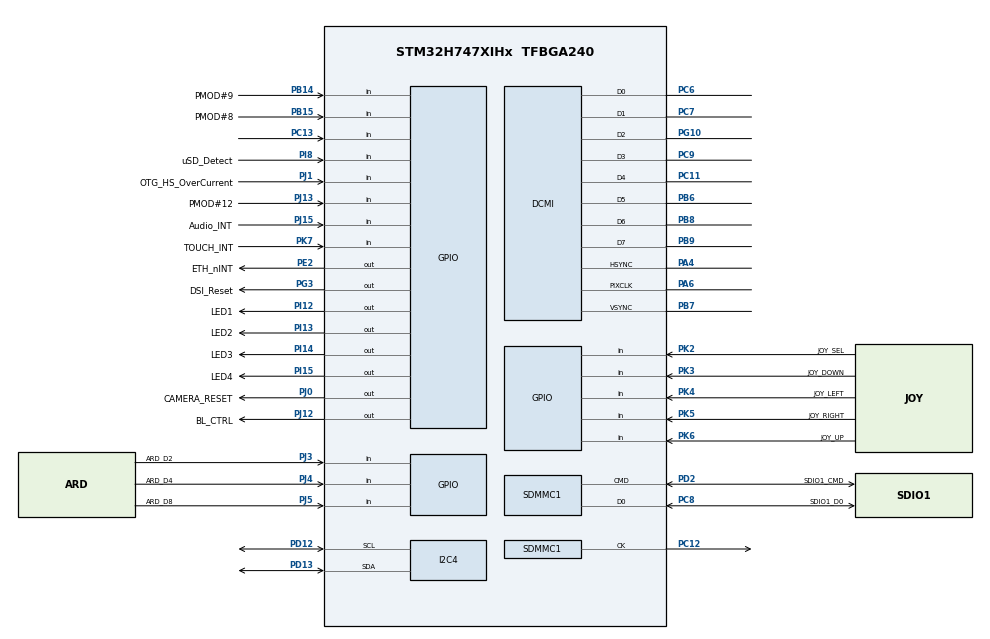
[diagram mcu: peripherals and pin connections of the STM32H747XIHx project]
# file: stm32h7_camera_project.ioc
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CortexM4.IPs=BDMA,DMA,FATFS_M4\:I,FREERTOS_M4\:I,IWDG2\:I,MDMA,NVIC2\:I,RCC,USB_DEVICE_M4\:I,USB_HOST_M4\:I,WWDG2\:I,TIM3\:I,PDM2PCM_M4\:I,PWR,RESMGR_UTILITY,SYS_M4\:I,CORTEX_M4\:I,GPIO,OPENAMP_M4\:I,VREFBUF,DEBUG
CortexM7.IPs=BDMA\:I,DMA\:I,FATFS_M7\:I,FREERTOS_M7\:I,IWDG1\:I,MDMA\:I,NVIC1\:I,RCC\:I,USB_DEVICE_M7\:I,USB_HOST_M7\:I,WWDG1\:I,CORTEX_M7\:I,DEBUG\:I,PDM2PCM_M7\:I,PWR\:I,RESMGR_UTILITY\:I,SYS\:I,GPIO\:I,OPENAMP_M7\:I,VREFBUF\:I,MEMORYMAP\:I,DCMI\:I,LTDC\:I,DSIHOST\:I,I2C4\:I,SDMMC1\:I
CortexM7.Pins=PC13,PJ0
DCMI.PCKPolarity=DCMI_PCKPOLARITY_RISING
DCMI.VSPolarity=DCMI_VSPOLARITY_HIGH
Dma.DCMI.0.Direction=DMA_PERIPH_TO_MEMORY
Dma.DCMI.0.EventEnable=DISABLE
Dma.DCMI.0.FIFOMode=DMA_FIFOMODE_DISABLE
Dma.DCMI.0.Instance=DMA1_Stream0
Dma.DCMI.0.MemDataAlignment=DMA_MDATAALIGN_WORD
Dma.DCMI.0.MemInc=DMA_MINC_ENABLE
Dma.DCMI.0.Mode=DMA_NORMAL
Dma.DCMI.0.PeriphDataAlignment=DMA_PDATAALIGN_WORD
Dma.DCMI.0.PeriphInc=DMA_PINC_DISABLE
Dma.DCMI.0.Polarity=HAL_DMAMUX_REQ_GEN_RISING
Dma.DCMI.0.Priority=DMA_PRIORITY_LOW
Dma.DCMI.0.RequestNumber=1
Dma.DCMI.0.SignalID=NONE
Dma.DCMI.0.SyncEnable=DISABLE
Dma.DCMI.0.SyncPolarity=HAL_DMAMUX_SYNC_NO_EVENT
Dma.DCMI.0.SyncRequestNumber=1
Dma.DCMI.0.SyncSignalID=NONE
Dma.Request0=DCMI
FATFS.BSP.number=1
FATFS0.BSP.STBoard=false
FATFS0.BSP.api=Unknown
FATFS0.BSP.instance=PI8
FATFS0.BSP.ip=GPIO
FATFS0.BSP.mode=Input
FATFS0.BSP.name=Detect_SDIO
FATFS0.BSP.solution=PI8
FATFS_M7.USE_DMA_CODE_SD=1
I2C4.Timing=0x10C0ECFF
Mcu.Family=STM32H7
Mcu.Name=STM32H747XIHx
Mcu.Package=TFBGA240
NVIC1.DCMI_IRQn=true\:0\:0\:false\:false\:true\:true\:true\:true
NVIC1.DMA1_Stream0_IRQn=true\:0\:0\:false\:false\:true\:false\:true\:true
NVIC1.PriorityGroup=NVIC_PRIORITYGROUP_4
NVIC1.SDMMC1_IRQn=true\:0\:0\:false\:false\:true\:true\:true\:true
NVIC2.PriorityGroup=NVIC_PRIORITYGROUP_4
PA0.GPIO_Label=PMOD\#1- USART2_CTS_NSS
PA0.Signal=USART2_CTS
PA0_C.GPIO_Label=ARD_A2
PA0_C.Signal=ADCx_INP0
PA1.GPIO_Label=ETH_REF_CLK
PA1.Signal=ETH_REF_CLK
PA10.GPIO_Label=STLINK_TX
PA10.Signal=USART1_RX
PA11.GPIO_Label=PMOD\#1
PA11.Signal=SPI2_NSS
PA12.GPIO_Label=SPI2_SCK
PA12.Signal=SPI2_SCK
PA13\ (JTMS/SWDIO).Mode=Serial_Wire
PA13\ (JTMS/SWDIO).PinAttribute=CortexM7
PA13\ (JTMS/SWDIO).Signal=DEBUG_JTMS-SWDIO
PA14\ (JTCK/SWCLK).Mode=Serial_Wire
PA14\ (JTCK/SWCLK).PinAttribute=CortexM7
PA14\ (JTCK/SWCLK).Signal=DEBUG_JTCK-SWCLK
PA1_C.GPIO_Label=ARD_A3
PA1_C.Signal=ADCx_INP1
PA2.GPIO_Label=ETH_MDIO
PA2.Signal=ETH_MDIO
PA3.GPIO_Label=ULPI_D0
PA3.Signal=USB_OTG_HS_ULPI_D0
PA4.GPIO_PuPd=GPIO_PULLDOWN
PA4.GPIO_Speed=GPIO_SPEED_FREQ_VERY_HIGH
PA4.Mode=Slave_8_bits_External_Synchro
PA4.PinAttribute=CortexM7
PA4.Signal=DCMI_HSYNC
PA5.GPIO_Label=ULPI_CK
PA5.Signal=USB_OTG_HS_ULPI_CK
PA6.GPIO_PuPd=GPIO_PULLDOWN
PA6.GPIO_Speed=GPIO_SPEED_FREQ_VERY_HIGH
PA6.Mode=Slave_8_bits_External_Synchro
PA6.PinAttribute=CortexM7
PA6.Signal=DCMI_PIXCLK
PA7.GPIO_Label=ETH_CRS_DV
PA7.Signal=ETH_CRS_DV
PA8.GPIO_Label=CEC_CK/MCO1
PA8.PinAttribute=Free
PA8.Signal=RCC_MCO_1
PA9.GPIO_Label=STLINK_RX
PA9.Signal=USART1_TX
PB0.GPIO_Label=ULPI_D1
PB0.Signal=USB_OTG_HS_ULPI_D1
PB1.GPIO_Label=ULPI_D2
PB1.Signal=USB_OTG_HS_ULPI_D2
PB10.GPIO_Label=ULPI_D3
PB10.Signal=USB_OTG_HS_ULPI_D3
PB11.GPIO_Label=ULPI_D4
PB11.Signal=USB_OTG_HS_ULPI_D4
PB12.GPIO_Label=ULPI_D5
PB12.Signal=USB_OTG_HS_ULPI_D5
PB13.GPIO_Label=ULPI_D6
PB13.Signal=USB_OTG_HS_ULPI_D6
PB14.GPIO_Label=PMOD\#9
PB14.PinAttribute=Free
PB14.Signal=GPIO_Input
PB15.GPIO_Label=PMOD\#8
PB15.PinAttribute=Free
PB15.Signal=GPIO_Input
PB2.GPIO_Label=QSPI_CLK
PB2.Signal=QUADSPI_CLK
PB5.GPIO_Label=ULPI_D7
PB5.Signal=USB_OTG_HS_ULPI_D7
PB6.GPIO_PuPd=GPIO_PULLDOWN
PB6.GPIO_Speed=GPIO_SPEED_FREQ_VERY_HIGH
PB6.Mode=Slave_8_bits_External_Synchro
PB6.PinAttribute=CortexM7
PB6.Signal=DCMI_D5
PB7.GPIO_PuPd=GPIO_PULLDOWN
PB7.GPIO_Speed=GPIO_SPEED_FREQ_VERY_HIGH
PB7.Mode=Slave_8_bits_External_Synchro
PB7.PinAttribute=CortexM7
PB7.Signal=DCMI_VSYNC
PB8.GPIO_PuPd=GPIO_PULLDOWN
PB8.GPIO_Speed=GPIO_SPEED_FREQ_VERY_HIGH
PB8.Mode=Slave_8_bits_External_Synchro
PB8.PinAttribute=CortexM7
PB8.Signal=DCMI_D6
PB9.GPIO_PuPd=GPIO_PULLDOWN
PB9.GPIO_Speed=GPIO_SPEED_FREQ_VERY_HIGH
PB9.Mode=Slave_8_bits_External_Synchro
PB9.PinAttribute=CortexM7
PB9.Signal=DCMI_D7
PC0.GPIO_Label=ULPI_STP
PC0.Signal=USB_OTG_HS_ULPI_STP
PC1.GPIO_Label=ETH_MDC/SAI4_D1
PC1.Signal=ETH_MDC
PC10.GPIO_Label=SDIO1_D2
PC10.PinAttribute=CortexM7
PC10.Signal=SDMMC1_D2
PC11.GPIO_PuPd=GPIO_PULLDOWN
PC11.GPIO_Speed=GPIO_SPEED_FREQ_VERY_HIGH
PC11.Mode=Slave_8_bits_External_Synchro
PC11.PinAttribute=CortexM7
PC11.Signal=DCMI_D4
PC12.Mode=SD_1_bit
PC12.PinAttribute=CortexM7
PC12.Signal=SDMMC1_CK
PC13.GPIO_PuPd=GPIO_PULLDOWN
PC13.PinAttribute=CortexM7
PC13.Signal=GPIO_Input
PC14-OSC32_IN\ (OSC32_IN).GPIO_Label=OSC32_IN
PC14-OSC32_IN\ (OSC32_IN).PinAttribute=Free
PC14-OSC32_IN\ (OSC32_IN).Signal=RCC_OSC32_IN
PC15-OSC32_OUT\ (OSC32_OUT).GPIO_Label=OSC32_OUT
PC15-OSC32_OUT\ (OSC32_OUT).PinAttribute=Free
PC15-OSC32_OUT\ (OSC32_OUT).Signal=RCC_OSC32_OUT
PC2.GPIO_Label=PMOD\#3
PC2.Signal=SPI2_MISO
PC2_C.GPIO_Label=ARD_A4
PC2_C.Signal=ADC3_INP0
PC3.GPIO_Label=PMOD\#2
PC3.Signal=SPI2_MOSI
PC3_C.GPIO_Label=ARD_A5
PC3_C.Signal=ADC3_INP1
PC4.GPIO_Label=ETH_RXD0
PC4.Signal=ETH_RXD0
PC5.GPIO_Label=ETH_RXD1
PC5.Signal=ETH_RXD1
PC6.GPIO_PuPd=GPIO_PULLDOWN
PC6.GPIO_Speed=GPIO_SPEED_FREQ_VERY_HIGH
PC6.Mode=Slave_8_bits_External_Synchro
PC6.PinAttribute=CortexM7
PC6.Signal=DCMI_D0
PC7.GPIO_PuPd=GPIO_PULLDOWN
PC7.GPIO_Speed=GPIO_SPEED_FREQ_VERY_HIGH
PC7.Mode=Slave_8_bits_External_Synchro
PC7.PinAttribute=CortexM7
PC7.Signal=DCMI_D1
PC8.GPIO_Label=SDIO1_D0
PC8.Mode=SD_1_bit
PC8.PinAttribute=CortexM7
PC8.Signal=SDMMC1_D0
PC9.GPIO_PuPd=GPIO_PULLDOWN
PC9.GPIO_Speed=GPIO_SPEED_FREQ_VERY_HIGH
PC9.Mode=Slave_8_bits_External_Synchro
PC9.PinAttribute=CortexM7
PC9.Signal=DCMI_D3
PD0.GPIO_Label=FMC_D2
PD0.Signal=FMC_D2_DA2
PD1.GPIO_Label=FMC_D3
PD1.Signal=FMC_D3_DA3
PD10.GPIO_Label=FMC_D15
PD10.Signal=FMC_D15_DA15
PD11.GPIO_Label=QSPI_BK1_IO0
PD11.Signal=QUADSPI_BK1_IO0
PD12.GPIO_Pu=GPIO_PULLUP
PD12.Mode=I2C
PD12.PinAttribute=CortexM7
PD12.Signal=I2C4_SCL
PD13.GPIO_Pu=GPIO_PULLUP
PD13.Mode=I2C
PD13.PinAttribute=CortexM7
PD13.Signal=I2C4_SDA
PD14.GPIO_Label=FMC_D0
PD14.Signal=FMC_D0_DA0
PD15.GPIO_Label=FMC_D1
PD15.Signal=FMC_D1_DA1
PD2.GPIO_Label=SDIO1_CMD
PD2.Mode=SD_1_bit
PD2.PinAttribute=CortexM7
PD2.Signal=SDMMC1_CMD
PD3.GPIO_Label=PMOD\#18_DFSDM_CKOUT
PD3.Signal=S_CKOUTDFSDM1
PD4.GPIO_Label=PMOD\#4- USART2_RTS
PD4.Signal=USART2_RTS
PD5.GPIO_Label=PMOD\#2- USART2_TX
PD5.Signal=USART2_TX
PD6.GPIO_Label=PMOD\#3- USART2_RX
PD6.Signal=USART2_RX
PD7.GPIO_Label=SPDIF_RX0
PD7.Signal=SPDIFRX1_IN0
PD8.GPIO_Label=FMC_D13
PD8.Signal=FMC_D13_DA13
PD9.GPIO_Label=FMC_D14
PD9.Signal=FMC_D14_DA14
PE0.GPIO_Label=FMC_NBL0
PE0.Signal=FMC_NBL0
PE1.GPIO_Label=FMC_NBL1
PE1.Signal=FMC_NBL1
PE10.GPIO_Label=FMC_D7
PE10.Signal=FMC_D7_DA7
PE11.GPIO_Label=FMC_D8
PE11.Signal=FMC_D8_DA8
PE12.GPIO_Label=FMC_D9
PE12.Signal=FMC_D9_DA9
PE13.GPIO_Label=FMC_D10
PE13.Signal=FMC_D10_DA10
PE14.GPIO_Label=FMC_D11
PE14.Signal=FMC_D11_DA11
PE15.GPIO_Label=FMC_D12
PE15.Signal=FMC_D12_DA12
PE2.GPIO_Label=ETH_nINT
PE2.PinAttribute=Free
PE2.Signal=GPIO_Output
PE3.GPIO_Label=SAI1_SD_B
PE3.Signal=SAI1_SD_B
PE4.GPIO_Label=SAI1_FS_A
PE4.Signal=SAI1_FS_A
PE5.GPIO_Label=SAI1_SCK_A
PE5.Signal=SAI1_SCK_A
PE6.GPIO_Label=SAI1_SD_A
PE6.Signal=SAI1_SD_A
PE7.GPIO_Label=FMC_D4
PE7.Signal=FMC_D4_DA4
PE8.GPIO_Label=FMC_D5
PE8.Signal=FMC_D5_DA5
PE9.GPIO_Label=FMC_D6
PE9.Signal=FMC_D6_DA6
PF0.GPIO_Label=FMC_A0
PF0.Signal=FMC_A0
PF1.GPIO_Label=FMC_A1
PF1.Signal=FMC_A1
PF10.GPIO_Label=ARD_A1
PF10.Signal=ADC3_INP6
PF11.GPIO_Label=FMC_SDRAS
PF11.Signal=FMC_SDNRAS
PF12.GPIO_Label=FMC_A6
PF12.Signal=FMC_A6
PF13.GPIO_Label=FMC_A7
PF13.Signal=FMC_A7
PF14.GPIO_Label=FMC_A8
PF14.Signal=FMC_A8
PF15.GPIO_Label=FMC_A9
PF15.Signal=FMC_A9
PF2.GPIO_Label=FMC_A2
PF2.Signal=FMC_A2
PF3.GPIO_Label=FMC_A3
PF3.Signal=FMC_A3
PF4.GPIO_Label=FMC_A4
PF4.Signal=FMC_A4
PF5.GPIO_Label=FMC_A5
PF5.Signal=FMC_A5
PF6.GPIO_Label=QSPI_BK1_IO3
PF6.Signal=QUADSPI_BK1_IO3
PF7.GPIO_Label=QSPI_BK1_IO2
PF7.Signal=QUADSPI_BK1_IO2
PF8.GPIO_Label=PMOD\#14/ARD_D3
PF8.Signal=S_TIM13_CH1
PF9.GPIO_Label=QSPI_BK1_IO1
PF9.Signal=QUADSPI_BK1_IO1
PG0.GPIO_Label=FMC_A10
PG0.Signal=FMC_A10
PG1.GPIO_Label=FMC_A11
PG1.Signal=FMC_A11
PG10.GPIO_PuPd=GPIO_PULLDOWN
PG10.GPIO_Speed=GPIO_SPEED_FREQ_VERY_HIGH
PG10.Mode=Slave_8_bits_External_Synchro
PG10.PinAttribute=CortexM7
PG10.Signal=DCMI_D2
PG11.GPIO_Label=ETH_TX_EN
PG11.Signal=ETH_TX_EN
PG12.GPIO_Label=ETH_TXD1
PG12.Signal=ETH_TXD1
PG13.GPIO_Label=ETH_TXD0
PG13.Signal=ETH_TXD0
PG14.GPIO_Label=QSPI_BK2_IO3
PG14.Signal=QUADSPI_BK2_IO3
PG15.GPIO_Label=FMC_SDCAS
PG15.Signal=FMC_SDNCAS
PG2.GPIO_Label=FMC_A12
PG2.Signal=FMC_A12
PG3.GPIO_Label=DSI_Reset
PG3.PinAttribute=Free
PG3.Signal=GPIO_Output
PG4.GPIO_Label=FMC_BA0
PG4.Signal=FMC_A14_BA0
PG5.Signal=FMC_A15_BA1
PG6.GPIO_Label=QSPI_BK1_NCS
PG6.Signal=QUADSPI_BK1_NCS
PG7.GPIO_Label=SAI1_MCLK_A
PG7.Signal=SAI1_MCLK_A
PG8.GPIO_Label=FMC_SDCLK
PG8.Signal=FMC_SDCLK
PG9.GPIO_Label=QSPI_BK2_IO2
PG9.Signal=QUADSPI_BK2_IO2
PH0-OSC_IN\ (PH0).GPIO_Label=OSC_IN
PH0-OSC_IN\ (PH0).Mode=HSE-External-Oscillator
PH0-OSC_IN\ (PH0).PinAttribute=Free
PH0-OSC_IN\ (PH0).Signal=RCC_OSC_IN
PH1-OSC_OUT\ (PH1).GPIO_Label=OSC_OUT
PH1-OSC_OUT\ (PH1).Mode=HSE-External-Oscillator
PH1-OSC_OUT\ (PH1).PinAttribute=Free
PH1-OSC_OUT\ (PH1).Signal=RCC_OSC_OUT
PH10.GPIO_Label=FMC_D18
PH10.Signal=FMC_D18
PH11.GPIO_Label=FMC_D19
PH11.Signal=FMC_D19
PH12.GPIO_Label=FMC_D20
PH12.Signal=FMC_D20
PH13.GPIO_Label=FMC_D21
PH13.Signal=FMC_D21
PH14.GPIO_Label=FMC_D22
PH14.Signal=FMC_D22
PH15.GPIO_Label=FMC_D23
PH15.Signal=FMC_D23
PH2.GPIO_Label=QSPI_BK2_IO0
PH2.Signal=QUADSPI_BK2_IO0
PH3.GPIO_Label=QSPI_BK2_IO1
PH3.Signal=QUADSPI_BK2_IO1
PH4.GPIO_Label=ULPI_NXT
PH4.Signal=USB_OTG_HS_ULPI_NXT
PH5.GPIO_Label=FMC_SDNWE
PH5.Signal=FMC_SDNWE
PH6.GPIO_Label=FMC_SDNE1
PH6.Signal=FMC_SDNE1
PH7.GPIO_Label=FMC_SDCKE1
PH7.Signal=FMC_SDCKE1
PH8.GPIO_Label=FMC_D16
PH8.Signal=FMC_D16
PH9.GPIO_Label=FMC_D17
PH9.Signal=FMC_D17
PI0.GPIO_Label=FMC_D24
PI0.Signal=FMC_D24
PI1.GPIO_Label=FMC_D25
PI1.Signal=FMC_D25
PI10.GPIO_Label=FMC_D31
PI10.Signal=FMC_D31
PI11.GPIO_Label=ULPI_DIR
PI11.Signal=USB_OTG_HS_ULPI_DIR
PI12.GPIO_Label=LED1
PI12.PinAttribute=Free
PI12.Signal=GPIO_Output
PI13.GPIO_Label=LED2
PI13.PinAttribute=Free
PI13.Signal=GPIO_Output
PI14.GPIO_Label=LED3
PI14.PinAttribute=Free
PI14.Signal=GPIO_Output
PI15.GPIO_Label=LED4
PI15.PinAttribute=Free
PI15.Signal=GPIO_Output
PI2.GPIO_Label=FMC_D26
PI2.Signal=FMC_D26
PI3.GPIO_Label=FMC_D27
PI3.Signal=FMC_D27
PI4.GPIO_Label=FMC_NBL2
PI4.Signal=FMC_NBL2
PI5.GPIO_Label=FMC_NBL3
PI5.Signal=FMC_NBL3
PI6.GPIO_Label=FMC_D28
PI6.Signal=FMC_D28
PI7.GPIO_Label=FMC_D29
PI7.Signal=FMC_D29
PI8.GPIO_Label=uSD_Detect
PI8.PinAttribute=Free
PI8.Signal=GPIO_Input
PI9.GPIO_Label=FMC_D30
PI9.Signal=FMC_D30
PJ0.GPIO_Label=CAMERA_RESET
PJ0.GPIO_PuPd=GPIO_PULLUP
PJ0.PinAttribute=CortexM7
PJ0.Signal=GPIO_Output
PJ1.GPIO_Label=OTG_HS_OverCurrent
PJ1.PinAttribute=Free
PJ1.Signal=GPIO_Input
PJ10.GPIO_Label=ARD_D11
PJ10.Signal=SPI5_MOSI
PJ11.GPIO_Label=ARD_D12
PJ11.Signal=SPI5_MISO
PJ12.GPIO_Label=BL_CTRL
PJ12.PinAttribute=Free
PJ12.Signal=GPIO_Output
PJ13.GPIO_Label=PMOD\#12
PJ13.PinAttribute=Free
PJ13.Signal=GPIO_Input
PJ15.GPIO_Label=Audio_INT
PJ15.PinAttribute=Free
PJ15.Signal=GPIO_Input
PJ3.GPIO_Label=ARD_D2
PJ3.PinAttribute=Free
PJ3.Signal=GPIO_Input
PJ4.GPIO_Label=ARD_D4
PJ4.PinAttribute=Free
PJ4.Signal=GPIO_Input
PJ5.GPIO_Label=ARD_D8
PJ5.PinAttribute=Free
PJ5.Signal=GPIO_Input
PJ6.GPIO_Label=ARD_D9
PJ6.Signal=S_TIM8_CH2
PJ7.GPIO_Label=ARD_D6
PJ7.Signal=TIM8_CH2N
PJ8.GPIO_Label=ARD_D1
PJ8.Signal=UART8_TX
PJ9.GPIO_Label=ARD_D0
PJ9.Signal=UART8_RX
PK0.GPIO_Label=ARD_D13
PK0.Signal=SPI5_SCK
PK1.GPIO_Label=ARD_D10
PK1.Signal=SPI5_NSS
PK2.GPIO_Label=JOY_SEL
PK2.PinAttribute=Free
PK2.Signal=GPIO_Input
PK3.GPIO_Label=JOY_DOWN
PK3.PinAttribute=Free
PK3.Signal=GPIO_Input
PK4.GPIO_Label=JOY_LEFT
PK4.PinAttribute=Free
PK4.Signal=GPIO_Input
PK5.GPIO_Label=JOY_RIGHT
PK5.PinAttribute=Free
PK5.Signal=GPIO_Input
PK6.GPIO_Label=JOY_UP
PK6.PinAttribute=Free
PK6.Signal=GPIO_Input
PK7.GPIO_Label=TOUCH_INT
PK7.PinAttribute=Free
PK7.Signal=GPIO_Input
ProjectManager.HeapSize=M4-0x400,M7-0x400
ProjectManager.StackSize=M4-0x800,M7-0x800
ProjectManager.TargetToolchain=STM32CubeIDE
RCC.ADCFreq_Value=150000000
RCC.APB1Freq_Value=100000000
RCC.APB2Freq_Value=100000000
RCC.APB3Freq_Value=100000000
RCC.APB4Freq_Value=100000000
RCC.CortexFreq_Value=200000000
RCC.D1PPRE=RCC_APB3_DIV2
RCC.D2PPRE1=RCC_APB1_DIV2
RCC.D2PPRE2=RCC_APB2_DIV2
RCC.D3PPRE=RCC_APB4_DIV2
RCC.DIVM1=2
RCC.DIVM2=2
RCC.DIVN1=32
RCC.DIVN2=12
RCC.DIVP2=1
RCC.DIVR2=1
RCC.HCLKFreq_Value=200000000
RCC.PLL2FRACN=0
RCC.PLLFRACN=0
RCC.PLLSourceVirtual=RCC_PLLSOURCE_HSE
RCC.PWR_Regulator_Voltage_Scale=PWR_REGULATOR_VOLTAGE_SCALE1
RCC.SDMMC1CLockSelection=RCC_SDMMCCLKSOURCE_PLL2
RCC.SYSCLKFreq_VALUE=200000000
RCC.SYSCLKSource=RCC_SYSCLKSOURCE_PLLCLK
RCC.SupplySource=PWR_DIRECT_SMPS_SUPPLY
RCC.USBFreq_Value=200000000
SH.ADCx_INP0.0=ADC1_INP0
SH.ADCx_INP1.0=ADC1_INP1
SH.FMC_A0.0=FMC_A0
SH.FMC_A1.0=FMC_A1
SH.FMC_A10.0=FMC_A10
SH.FMC_A11.0=FMC_A11
SH.FMC_A12.0=FMC_A12
SH.FMC_A14_BA0.0=FMC_BA0
SH.FMC_A15_BA1.0=FMC_BA1
SH.FMC_A2.0=FMC_A2
SH.FMC_A3.0=FMC_A3
SH.FMC_A4.0=FMC_A4
SH.FMC_A5.0=FMC_A5
SH.FMC_A6.0=FMC_A6
SH.FMC_A7.0=FMC_A7
SH.FMC_A8.0=FMC_A8
SH.FMC_A9.0=FMC_A9
SH.FMC_D0_DA0.0=FMC_D0
SH.FMC_D10_DA10.0=FMC_D10
SH.FMC_D11_DA11.0=FMC_D11
SH.FMC_D12_DA12.0=FMC_D12
SH.FMC_D13_DA13.0=FMC_D13
SH.FMC_D14_DA14.0=FMC_D14
SH.FMC_D15_DA15.0=FMC_D15
SH.FMC_D16.0=FMC_D16
SH.FMC_D17.0=FMC_D17
SH.FMC_D18.0=FMC_D18
SH.FMC_D19.0=FMC_D19
SH.FMC_D1_DA1.0=FMC_D1
SH.FMC_D20.0=FMC_D20
SH.FMC_D21.0=FMC_D21
SH.FMC_D22.0=FMC_D22
SH.FMC_D23.0=FMC_D23
SH.FMC_D24.0=FMC_D24
SH.FMC_D25.0=FMC_D25
SH.FMC_D26.0=FMC_D26
SH.FMC_D27.0=FMC_D27
SH.FMC_D28.0=FMC_D28
SH.FMC_D29.0=FMC_D29
SH.FMC_D2_DA2.0=FMC_D2
SH.FMC_D30.0=FMC_D30
SH.FMC_D31.0=FMC_D31
SH.FMC_D3_DA3.0=FMC_D3
SH.FMC_D4_DA4.0=FMC_D4
SH.FMC_D5_DA5.0=FMC_D5
SH.FMC_D6_DA6.0=FMC_D6
SH.FMC_D7_DA7.0=FMC_D7
SH.FMC_D8_DA8.0=FMC_D8
SH.FMC_D9_DA9.0=FMC_D9
SH.FMC_NBL0.0=FMC_NBL0
SH.FMC_NBL1.0=FMC_NBL1
SH.FMC_NBL2.0=FMC_NBL2
SH.FMC_NBL3.0=FMC_NBL3
SH.FMC_SDCLK.0=FMC_SDCLK
SH.FMC_SDNCAS.0=FMC_SDNCAS
SH.FMC_SDNRAS.0=FMC_SDNRAS
SH.FMC_SDNWE.0=FMC_SDNWE
SH.S_CKOUTDFSDM1.0=DFSDM1_CKOUT
SH.S_TIM13_CH1.0=TIM13_CH1
SH.S_TIM8_CH2.0=TIM8_CH2
VP_FATFS_M7_VS_SDIO.Mode=SDIO
VP_MEMORYMAP_VS_MEMORYMAP.Mode=CurAppReg
VP_SYS_M4_VS_Systick.Mode=SysTick
board=STM32H747I-DISC1

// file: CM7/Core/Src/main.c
/* USER CODE BEGIN Header */
/**
  ******************************************************************************
  * @file           : main.c
  * @brief          : Main program body
  ******************************************************************************
  * @attention
  *
  * Copyright (c) 2025 STMicroelectronics.
  * All rights reserved.
  *
  * This software is licensed under terms that can be found in the LICENSE file
  * in the root directory of this software component.
  * If no LICENSE file comes with this software, it is provided AS-IS.
  *
  ******************************************************************************
  */
/* USER CODE END Header */
#include "main.h"
#include "fatfs.h"

/* USER CODE BEGIN Includes */
#include "common.h"
#include "ov7670.h"

/* USER CODE END Includes */

/* USER CODE BEGIN PD */

#ifndef HSEM_ID_0
#define HSEM_ID_0 (0U) /* HW semaphore 0*/
#endif

/* USER CODE END PD */

DCMI_HandleTypeDef hdcmi;
DMA_HandleTypeDef hdma_dcmi;

I2C_HandleTypeDef hi2c4;

SD_HandleTypeDef hsd1;

void SystemClock_Config(void);
static void MX_GPIO_Init(void);
static void MX_DMA_Init(void);
static void MX_DCMI_Init(void);
static void MX_I2C4_Init(void);
static void MX_SDMMC1_SD_Init(void);

/* USER CODE BEGIN 0 */
int prev_button_state = 0;
/* USER CODE END 0 */

int main(void)
{

/* USER CODE BEGIN Boot_Mode_Sequence_0 */
  int32_t timeout;
/* USER CODE END Boot_Mode_Sequence_0 */

/* USER CODE BEGIN Boot_Mode_Sequence_1 */
  /* Wait until CPU2 boots and enters in stop mode or timeout*/
  timeout = 0xFFFF;
  while((__HAL_RCC_GET_FLAG(RCC_FLAG_D2CKRDY) != RESET) && (timeout-- > 0));
  if ( timeout < 0 )
  {
  Error_Handler();
  }
/* USER CODE END Boot_Mode_Sequence_1 */
  /* MCU Configuration--------------------------------------------------------*/

  /* Reset of all peripherals, Initializes the Flash interface and the Systick. */
  HAL_Init();

  /* Configure the system clock */
  SystemClock_Config();
/* USER CODE BEGIN Boot_Mode_Sequence_2 */
/* When system initialization is finished, Cortex-M7 will release Cortex-M4 by means of
HSEM notification */
/*HW semaphore Clock enable*/
__HAL_RCC_HSEM_CLK_ENABLE();
/*Take HSEM */
HAL_HSEM_FastTake(HSEM_ID_0);
/*Release HSEM in order to notify the CPU2(CM4)*/
HAL_HSEM_Release(HSEM_ID_0,0);
/* wait until CPU2 wakes up from stop mode */
timeout = 0xFFFF;
while((__HAL_RCC_GET_FLAG(RCC_FLAG_D2CKRDY) == RESET) && (timeout-- > 0));
if ( timeout < 0 )
{
Error_Handler();
}
/* USER CODE END Boot_Mode_Sequence_2 */

  /* Initialize all configured peripherals */
  MX_GPIO_Init();
  MX_DMA_Init();
  MX_DCMI_Init();
  MX_I2C4_Init();
  MX_SDMMC1_SD_Init();
  MX_FATFS_Init();
  /* USER CODE BEGIN 2 */

  ov7670_init(&hdcmi, &hdcmi, &hi2c4);

  ov7670_config(OV7670_MODE_QVGA_RGB565);

  /* USER CODE END 2 */

  /* Infinite loop */
  /* USER CODE BEGIN WHILE */
  while (1)
  {

	 HAL_Delay(10);
	 int button_state = HAL_GPIO_ReadPin(GPIOC, GPIO_PIN_13);
	 if (button_state && !prev_button_state)
	 {
		 ov7670_startCap(OV7670_CAP_SINGLE_FRAME,CAM_BUFFER);
		 writeBMPfile();
	 }
	 prev_button_state = button_state;

    /* USER CODE END WHILE */

  }
}

void SystemClock_Config(void)
{
  RCC_OscInitTypeDef RCC_OscInitStruct = {0};
  RCC_ClkInitTypeDef RCC_ClkInitStruct = {0};

  /** Supply configuration update enable
  */
  HAL_PWREx_ConfigSupply(PWR_DIRECT_SMPS_SUPPLY);

  /** Configure the main internal regulator output voltage
  */
  __HAL_PWR_VOLTAGESCALING_CONFIG(PWR_REGULATOR_VOLTAGE_SCALE1);

  while(!__HAL_PWR_GET_FLAG(PWR_FLAG_VOSRDY)) {}

  /** Initializes the RCC Oscillators according to the specified parameters
  * in the RCC_OscInitTypeDef structure.
  */
  RCC_OscInitStruct.OscillatorType = RCC_OSCILLATORTYPE_HSE;
  RCC_OscInitStruct.HSEState = RCC_HSE_ON;
  RCC_OscInitStruct.PLL.PLLState = RCC_PLL_ON;
  RCC_OscInitStruct.PLL.PLLSource = RCC_PLLSOURCE_HSE;
  RCC_OscInitStruct.PLL.PLLM = 2;
  RCC_OscInitStruct.PLL.PLLN = 32;
  RCC_OscInitStruct.PLL.PLLP = 2;
  RCC_OscInitStruct.PLL.PLLQ = 2;
  RCC_OscInitStruct.PLL.PLLR = 2;
  RCC_OscInitStruct.PLL.PLLRGE = RCC_PLL1VCIRANGE_3;
  RCC_OscInitStruct.PLL.PLLVCOSEL = RCC_PLL1VCOWIDE;
  RCC_OscInitStruct.PLL.PLLFRACN = 0;
  if (HAL_RCC_OscConfig(&RCC_OscInitStruct) != HAL_OK)
  {
    Error_Handler();
  }

  /** Initializes the CPU, AHB and APB buses clocks
  */
  RCC_ClkInitStruct.ClockType = RCC_CLOCKTYPE_HCLK|RCC_CLOCKTYPE_SYSCLK
                              |RCC_CLOCKTYPE_PCLK1|RCC_CLOCKTYPE_PCLK2
                              |RCC_CLOCKTYPE_D3PCLK1|RCC_CLOCKTYPE_D1PCLK1;
  RCC_ClkInitStruct.SYSCLKSource = RCC_SYSCLKSOURCE_PLLCLK;
  RCC_ClkInitStruct.SYSCLKDivider = RCC_SYSCLK_DIV1;
  RCC_ClkInitStruct.AHBCLKDivider = RCC_HCLK_DIV1;
  RCC_ClkInitStruct.APB3CLKDivider = RCC_APB3_DIV2;
  RCC_ClkInitStruct.APB1CLKDivider = RCC_APB1_DIV2;
  RCC_ClkInitStruct.APB2CLKDivider = RCC_APB2_DIV2;
  RCC_ClkInitStruct.APB4CLKDivider = RCC_APB4_DIV2;

  if (HAL_RCC_ClockConfig(&RCC_ClkInitStruct, FLASH_LATENCY_2) != HAL_OK)
  {
    Error_Handler();
  }
}

static void MX_DCMI_Init(void)
{

  hdcmi.Instance = DCMI;
  hdcmi.Init.SynchroMode = DCMI_SYNCHRO_HARDWARE;
  hdcmi.Init.PCKPolarity = DCMI_PCKPOLARITY_RISING;
  hdcmi.Init.VSPolarity = DCMI_VSPOLARITY_HIGH;
  hdcmi.Init.HSPolarity = DCMI_HSPOLARITY_LOW;
  hdcmi.Init.CaptureRate = DCMI_CR_ALL_FRAME;
  hdcmi.Init.ExtendedDataMode = DCMI_EXTEND_DATA_8B;
  hdcmi.Init.JPEGMode = DCMI_JPEG_DISABLE;
  hdcmi.Init.ByteSelectMode = DCMI_BSM_ALL;
  hdcmi.Init.ByteSelectStart = DCMI_OEBS_ODD;
  hdcmi.Init.LineSelectMode = DCMI_LSM_ALL;
  hdcmi.Init.LineSelectStart = DCMI_OELS_ODD;
  if (HAL_DCMI_Init(&hdcmi) != HAL_OK)
  {
    Error_Handler();
  }

}

static void MX_I2C4_Init(void)
{

  hi2c4.Instance = I2C4;
  hi2c4.Init.Timing = 0x10C0ECFF;
  hi2c4.Init.OwnAddress1 = 0;
  hi2c4.Init.AddressingMode = I2C_ADDRESSINGMODE_7BIT;
  hi2c4.Init.DualAddressMode = I2C_DUALADDRESS_DISABLE;
  hi2c4.Init.OwnAddress2 = 0;
  hi2c4.Init.OwnAddress2Masks = I2C_OA2_NOMASK;
  hi2c4.Init.GeneralCallMode = I2C_GENERALCALL_DISABLE;
  hi2c4.Init.NoStretchMode = I2C_NOSTRETCH_DISABLE;
  if (HAL_I2C_Init(&hi2c4) != HAL_OK)
  {
    Error_Handler();
  }

  /** Configure Analogue filter
  */
  if (HAL_I2CEx_ConfigAnalogFilter(&hi2c4, I2C_ANALOGFILTER_ENABLE) != HAL_OK)
  {
    Error_Handler();
  }

  /** Configure Digital filter
  */
  if (HAL_I2CEx_ConfigDigitalFilter(&hi2c4, 0) != HAL_OK)
  {
    Error_Handler();
  }

}

static void MX_SDMMC1_SD_Init(void)
{

  hsd1.Instance = SDMMC1;
  hsd1.Init.ClockEdge = SDMMC_CLOCK_EDGE_RISING;
  hsd1.Init.ClockPowerSave = SDMMC_CLOCK_POWER_SAVE_DISABLE;
  hsd1.Init.BusWide = SDMMC_BUS_WIDE_1B;
  hsd1.Init.HardwareFlowControl = SDMMC_HARDWARE_FLOW_CONTROL_DISABLE;
  hsd1.Init.ClockDiv = 0;
  if (HAL_SD_Init(&hsd1) != HAL_OK)
  {
    Error_Handler();
  }

}

static void MX_DMA_Init(void)
{

  /* DMA controller clock enable */
  __HAL_RCC_DMA1_CLK_ENABLE();

  /* DMA interrupt init */
  /* DMA1_Stream0_IRQn interrupt configuration */
  HAL_NVIC_SetPriority(DMA1_Stream0_IRQn, 0, 0);
  HAL_NVIC_EnableIRQ(DMA1_Stream0_IRQn);

}

static void MX_GPIO_Init(void)
{
  GPIO_InitTypeDef GPIO_InitStruct = {0};

  /* GPIO Ports Clock Enable */
  __HAL_RCC_GPIOG_CLK_ENABLE();
  __HAL_RCC_GPIOC_CLK_ENABLE();
  __HAL_RCC_GPIOB_CLK_ENABLE();
  __HAL_RCC_GPIOA_CLK_ENABLE();
  __HAL_RCC_GPIOD_CLK_ENABLE();
  __HAL_RCC_GPIOI_CLK_ENABLE();
  __HAL_RCC_GPIOJ_CLK_ENABLE();

  /*Configure GPIO pin Output Level */
  HAL_GPIO_WritePin(CAMERA_RESET_GPIO_Port, CAMERA_RESET_Pin, GPIO_PIN_RESET);

  /*Configure GPIO pin : PC13 */
  GPIO_InitStruct.Pin = GPIO_PIN_13;
  GPIO_InitStruct.Mode = GPIO_MODE_INPUT;
  GPIO_InitStruct.Pull = GPIO_PULLDOWN;
  HAL_GPIO_Init(GPIOC, &GPIO_InitStruct);

  /*Configure GPIO pin : uSD_Detect_Pin */
  GPIO_InitStruct.Pin = uSD_Detect_Pin;
  GPIO_InitStruct.Mode = GPIO_MODE_INPUT;
  GPIO_InitStruct.Pull = GPIO_NOPULL;
  HAL_GPIO_Init(uSD_Detect_GPIO_Port, &GPIO_InitStruct);

  /*Configure GPIO pin : CAMERA_RESET_Pin */
  GPIO_InitStruct.Pin = CAMERA_RESET_Pin;
  GPIO_InitStruct.Mode = GPIO_MODE_OUTPUT_PP;
  GPIO_InitStruct.Pull = GPIO_PULLUP;
  GPIO_InitStruct.Speed = GPIO_SPEED_FREQ_LOW;
  HAL_GPIO_Init(CAMERA_RESET_GPIO_Port, &GPIO_InitStruct);

}

void Error_Handler(void)
{
  __disable_irq();
  while (1)
  {
  }
}
